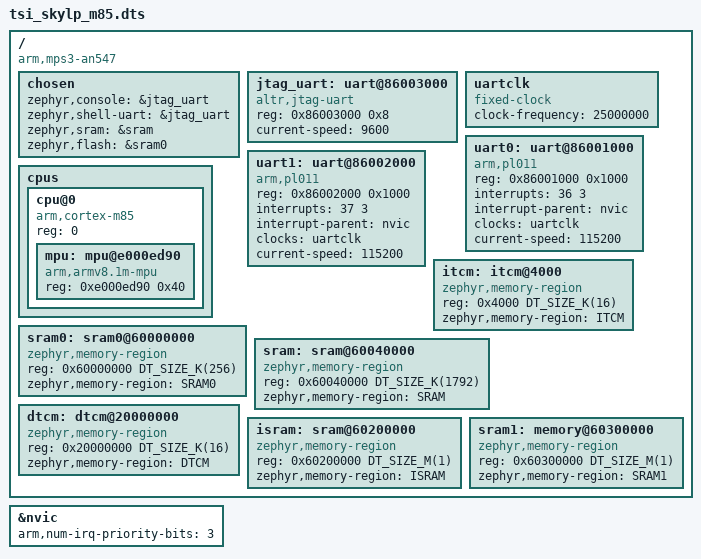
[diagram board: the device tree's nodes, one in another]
/*
 * Copyright (c) 2024 TSI
 * Copyright 2022 Arm Limited and/or its affiliates <open-source-office@arm.com>
 *
 * SPDX-License-Identifier: Apache-2.0
 */

/dts-v1/;

#include <arm/armv8.1-m.dtsi>
#include <zephyr/dt-bindings/i2c/i2c.h>
#include <zephyr/dt-bindings/input/input-event-codes.h>
#include <mem.h>

/ {
	compatible = "arm,mps3-an547";
	#address-cells = <1>;
	#size-cells = <1>;

	chosen {
		/* Default console: JTAG UART (Bittware). ProFPGA builds override
		 * this to &uart0 (PL011) via boards/tsi/skylp/profpga.overlay.
		 */
		zephyr,console = &jtag_uart;
		zephyr,shell-uart = &jtag_uart;
		zephyr,sram = &sram;
		zephyr,flash = &sram0;
	};

	jtag_uart: uart@86003000 {
		compatible = "altr,jtag-uart";
		reg = <0x86003000 0x8>;
		status = "enabled";
	};

	uartclk: uartclk {
		compatible = "fixed-clock";
		clock-frequency = <25000000>;
		#clock-cells = <0>;
	};

	uart0: uart@86001000 {
		compatible = "arm,pl011";
		reg = <0x86001000 0x1000>;
		interrupts = <36 3>;    /* unused in polled mode (CONFIG_UART_INTERRUPT_DRIVEN off) */
		interrupt-parent = <&nvic>;
		clocks = <&uartclk>;
		current-speed = <115200>;
		status = "okay";
	};

	uart1: uart@86002000 {
		compatible = "arm,pl011";
		reg = <0x86002000 0x1000>;
		interrupts = <37 3>;    /* unused in polled mode */
		interrupt-parent = <&nvic>;
		clocks = <&uartclk>;
		current-speed = <115200>;
		status = "okay";
	};

	cpus {
		#address-cells = <1>;
		#size-cells = <0>;

		cpu@0 {
			device_type = "cpu";
			compatible = "arm,cortex-m85";
			reg = <0>;
			#address-cells = <1>;
			#size-cells = <1>;

			mpu: mpu@e000ed90 {
				compatible = "arm,armv8.1m-mpu";
				reg = <0xe000ed90 0x40>;
			};
		};
	};

	/* We utilize the secure addresses, if you subtract 0x10000000
	 * you'll get the non-secure alias
	 */
	itcm: itcm@4000 {   /* alias @ 0x4000 */
		compatible = "zephyr,memory-region";
		reg = <0x4000 DT_SIZE_K(16)>;
		zephyr,memory-region = "ITCM";
	};

	/*sram0: sram0@60000000 {	 alias @ 0x60000000 */
/*		reg = <0x60000000 DT_SIZE_K(256)>; */
	sram0: sram0@60000000 {	/* alias @ 0x60000000 */
		compatible = "zephyr,memory-region";
		reg = <0x60000000 DT_SIZE_K(256)>;
		zephyr,memory-region = "SRAM0";
	};

	sram: sram@60040000 {	/* alias @ 0x60040000 */
		compatible = "zephyr,memory-region", "mmio-sram";
		reg = <0x60040000 DT_SIZE_K(1792)>;
		zephyr,memory-region = "SRAM";
	};

	dtcm: dtcm@20000000 {	/* alias @ 0x20000000 */
		compatible = "zephyr,memory-region";
		reg = <0x20000000 DT_SIZE_K(16)>;
		zephyr,memory-region = "DTCM";
	};

	isram: sram@60200000 {/* alias @ 0x60200000, lower 1MB of 2 MB SRAM1 */
		compatible = "zephyr,memory-region", "mmio-sram";
		reg = <0x60200000 DT_SIZE_M(1)>;
		zephyr,memory-region = "ISRAM";
	};

	/* Higher 1 MB of 2MB high SRAM */
	sram1: memory@60300000 {
		device_type = "memory";
		compatible = "zephyr,memory-region";
		reg = <0x60300000 DT_SIZE_M(1)>;
		zephyr,memory-region = "SRAM1";
	};

	/*soc {
		peripheral@71000000 {
			#address-cells = <1>;
			#size-cells = <1>;
			ranges = <0x0 0x71000000 0x1effffff>;

			 #include "tsi_skylp_m85-common.dtsi"
		};
	};*/
};

&jtag_uart {
	status = "okay";
	current-speed = <9600>;
};

&nvic {
	arm,num-irq-priority-bits = <3>;
};
